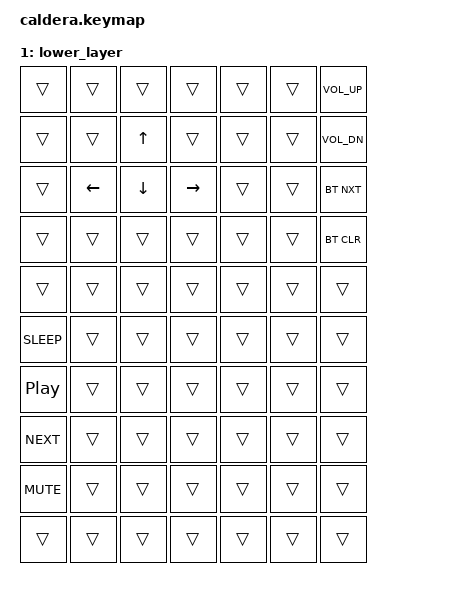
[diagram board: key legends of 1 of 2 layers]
#include <behaviors.dtsi>
#include <dt-bindings/zmk/keys.h>
#include <dt-bindings/zmk/bt.h>

#define lower_layer 1

/ {
        keymap {
                compatible = "zmk,keymap";

                default_layer {
                        bindings = <
   &kp ESC   &kp 1 &kp 2    &kp 3    &kp 4   &kp 5     &kp F1
   &kp TAB   &kp Q &kp W    &kp E    &kp R   &kp T     &kp F2
   &kp LCTRL &kp A &kp S    &kp D    &kp F   &kp G     &kp F3
   &mo 1     &kp Z &kp X    &kp C    &kp V   &kp B     &kp F4
                &kp LALT &kp LGUI &kp RET &kp SPACE &kp LSHIFT
                                                                &kp F5     &kp 6     &kp 7    &kp 8     &kp 9     &kp 0    &kp MINUS
                                                                &kp F6     &kp Y     &kp U    &kp I     &kp O     &kp P    &kp EQUAL
                                                                &kp F7     &kp H     &kp J    &kp K     &kp L     &kp SEMI &kp APOS
                                                                &kp F8     &kp N     &kp M    &kp COMMA &kp DOT   &kp FSLH &kp BSLH
                                                                &kp RSHIFT &kp SPACE &kp BSPC &kp DEL   &kp PSCRN
                        >;
                };
                lower_layer {
                        bindings = <
   &trans &trans   &trans    &trans    &trans &trans &kp C_VOL_UP
   &trans &trans   &kp UP    &trans    &trans &trans &kp C_VOL_DN
   &trans &kp LEFT &kp DOWN  &kp RIGHT &trans &trans &bt BT_NXT  
   &trans &trans   &trans    &trans    &trans &trans &bt BT_CLR  
   &trans &trans   &trans    &trans    &trans &trans &trans      
                                                                &kp K_SLEEP      &trans &trans &trans &trans &trans &trans
                                                                &kp C_PLAY_PAUSE &trans &trans &trans &trans &trans &trans
                                                                &kp C_NEXT       &trans &trans &trans &trans &trans &trans
                                                                &kp C_MUTE       &trans &trans &trans &trans &trans &trans
                                                                &trans           &trans &trans &trans &trans &trans &trans
                        >;
                };
        };
};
